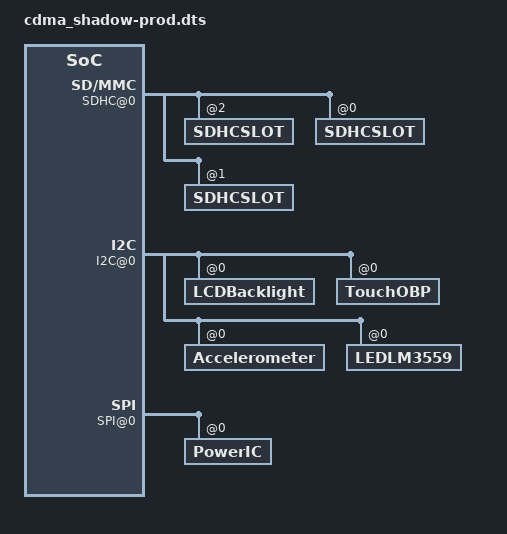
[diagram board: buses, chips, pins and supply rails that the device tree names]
/* Motorola Droid X - production version */

/dts-v1/;

/ {

	Aliases@0 {
	};

	Chosen@0 {
		bp_model = "CDMA";
		formfactor = <0x3000000>;
		last_compat_version = <0xfcb73201>;
		omap3630_rev = <0x36301000>;
		product = <0x36120000>;
		usb_id_prod_name = "MB810";
		version = <0xfcb73201>;
	};

	Machine@0 {
		cpu_tier = "10";
	};

	System@0 {

		DisplayBacklight@0 {
			tablet_lcd = [01];
			class = "DisplayBacklight";
			ruth_lcd = [00];
			type = <0xd000000>;
		};

		Display@1 {
			gpio_int = <0x19000000>;
			gpio_pwr_en = <0x1a000000>;
			gpio_mux_select = <0x7000000>;
			gpio_mux_en = <0x45000000>;
			class = "Display";
			type = <0x1900>;
			cec_reg_name = "vusb";
		};

		Keyreset@0 {
			keyup = <0x10010000 0x0>;
			crash = <0x73000000>;
			class = "Keyreset";
			keydown = <0x8b000000 0x9e000000 0xd3000000 0x0>;
			type = <0x11000000>;
		};

		LEDController@2 {
			dev_name_green = "green";
			class = "LEDController";
			dev_name_red = "red";
			type = <0x5002100>;
			dev_name_blue = "blue";
		};

		SDHC@0 {
			bind_device_to_host = [01];
			class = "SDHC";
			type = <0x8000300>;

			SDHCSLOT@2 {
				card_detection = <0x1000000>;
				sdcnum = [03];
				host_capability = <0x11000000>;
				card_connect = <0x3000000>;
			};

			SDHCSLOT@0 {
				card_detection = <0x1000000>;
				host_capability = <0x11000000>;
				pwr_supply = <0x2000000>;
				card_connect = <0x1000000>;
			};

			SDHCSLOT@1 {
				card_detection = <0x0>;
				host_capability = <0x11010000>;
				card_connect = <0x2000000>;
			};
		};

		PROX@0 {
			pwr_supply = <0x0>;
			class = "PROX";
			type = <0x1b00>;
		};

		I2C@0 {
			bus3devices = "HP_GEN_LENS,tda19989,ov8810,lm3559_led";
			bus1devices = "qtouch-obp-ts,lm3530_led,airc";
			class = "I2C";
			bus2devices = "akm8973,kxtf9";
			type = <0x3000100>;

			LCDBacklight@0 {
				zone_target_4 = [7b];
				zone_target_3 = [7b];
				zone_target_0 = [15];
				als_resistor_sel = [02];
				manual_current = [37];
				als_config = [ac];
				zone_boundary_2 = [c6];
				als_zone_info = [00];
				zone_boundary_3 = [c6];
				upper_curr_sel = [06];
				lens_loss_coeff = [01];
				gen_config = [3b];
				zone_boundary_0 = [03];
				class = "LCDBacklight";
				zone_target_1 = [30];
				zone_target_2 = [68];
				brightness_control = [00];
				lower_curr_sel = [03];
				manual_als_config = [2d];
				type = <0x2000b00>;
				zone_boundary_1 = [54];
				power_up_gen_config = [27];
				brightness_ramp = [00];
			};

			TouchOBP@0 {
				abs_min_x = <0x23000000>;
				abs_min_y = <0x14000000>;
				abs_max_w = <0x23000000>;
				abs_max_x = <0xf5030000>;
				abs_max_y = <0xe8030000>;
				boot_i2c_address = [24];
				class = "TouchOBP";
				i2c,address = <0x4a000000>;
				obj_t22 = [05 00 00 19 00 e7 ff 04 14 00 00 07 0b 0e 10 16 04];
				obj_t28 = [01 00 03 04 08 0a];
				obj_t7 = [0a 0a 19];
				obj_t8 = <0xc000000 0x96000500>;
				obj_t9 = [0b 00 00 13 0b 00 10 2d 02 04 19 0a 03 30 02 05 05 05 00 00 00 00 05 00 2f 0c ca 37 86 5f];
				nv_checksum = <0xbcf00000>;
				type = <0x6000700>;
			};

			Accelerometer@0 {
				axis_map_x = [00];
				axis_map_y = [01];
				axis_map_z = [02];
				class = "Accelerometer";
				negate_x = [01];
				negate_y = [00];
				negate_z = [01];
				type = <0x1800>;
			};

			LEDLM3559@0 {
				device_available = [01];
				class = "LEDLM3559";
				lm3559_flags = [2c];
				type = <0x3000b00>;
			};
		};

		Keypad@0 {
			class = "Keypad";
			columnregister = <0x2b000000 0x38000000 0x39000000 0x35000000 0x36000000 0x37000000 0x3a000000 0x3f000000>;
			columns = <0x8000000>;
			dev_name = "cdma_shadow-keypad";
			wakeints = <0x1000000>;
			maps = <0x73007200 0x8b00e700 0x0 0xd400 0xd3000000 0x0 0x0 0x66009e00 0xd9000000 0x0 0x0 0x0 0x38000000 0x6000b00 0x0 0xe300 0x700 0x2000000 0x0 0x3d000000 0x8000300 0x0 0x3e00 0x900 0x4000000 0x0 0xe4000000 0xa000500>;
			rowregister = <0x27000000 0x25000000 0x28000000 0x29000000 0x26000000 0x23000000 0x22000000>;
			rows = <0x7000000>;
			keycodes-bugtogo = <0x8b000000 0xd9000000>;
			wakeupregister = <0x27000000>;
			type = <0x1000000>;
		};

		Modem@0 {
			class = "Modem";
			type = <0x1e00>;
		};

		GPIODev@0 {
			class = "GPIODev";
			init = <0x3b000000 0x6770735f 0x72657365 0x74002020 0x20202020 0x20202000 0x8000000 0x17000000 0x6770735f 0x7374616e 0x64627900 0x20202020 0x20202000 0x8000000 0x8000000 0x62745f77 0x616b6500 0x20202020 0x20202020 0x20202000 0x8000000 0x7000000 0x68646d69 0x5f6d7578 0x5f73656c 0x65637400 0x20202000 0x8000000 0x45000000 0x68646d69 0x5f6d7578 0x5f656e5f 0x6e002020 0x20202000 0x8000000 0xb2000000 0x62745f68 0x6f737477 0x616b6500 0x20202020 0x20202000 0x2000000>;
			type = <0xa000300>;
		};

		LinearVibrator@0 {
			gpio = <0x9000000>;
			cycle = <0x710c0000>;
			class = "LinearVibrator";
			period = <0xe2180000>;
			supported = <0x1000000>;
			type = <0x2000000>;
			linear_vib_only = <0x1000000>;
		};

		Display@0 {
			disp_intf = [04];
			dsi_data2_lane = [03];
			pixel_fmt = <0x5000000>;
			pck_div = [04 00];
			dsi_data1_pol = [00];
			dsi_data1_lane = [02];
			dispc_timing_hbp = [02 00];
			dispc_timing_hfp = [00 00];
			dsi_clk_pol = [00];
			regm = [aa 00];
			dispc_timing_vfp = [00 00];
			dsi_clk_lane = [01];
			lp_clk_div = [0a 00];
			regm4 = [05 00];
			class = "Display";
			lck_div = [01 00];
			dispc_timing_hsw = [02 00];
			dispc_timing_vbp = [01 00];
			phy_height_mm = [5f 00];
			disp_hw_type = [04];
			gpio_reset = <0x7e000000>;
			type = <0x1a00>;
			byte_pp = [03];
			phy_width_mm = [35 00];
			regm3 = [05 00];
			dispc_timing_vsw = [01 00];
			height = [56 03];
			width = [e0 01];
			regn = [0d 00];
			dsi_data2_pol = [00];
		};

		GPIO@0 {
			class = "GPIO";
			signalmap = <0x1c000000 0x616b6d38 0x3937335f 0x72657365 0x74202020 0x20202000 0xa0000000 0x6c6d3335 0x33305f72 0x65736574 0x20202020 0x20202000 0x1d000000 0x6c6d3335 0x33305f69 0x6e742020 0x20202020 0x20202000 0xaf000000 0x616b6d38 0x3937335f 0x696e7420 0x20202020 0x20202000 0xb3000000 0x62745f72 0x65736574 0x5f622020 0x20202020 0x20202000 0x8000000 0x62745f77 0x616b655f 0x62202020 0x20202020 0x20202000 0xb2000000 0x62745f68 0x6f73745f 0x77616b65 0x5f622020 0x20202000 0xba000000 0x776c616e 0x5f726573 0x65742020 0x20202020 0x20202000 0x64000000 0x73696c65 0x6e63655f 0x64617461 0x20202020 0x20202000 0xb5000000 0x7669625f 0x636f6e74 0x726f6c5f 0x656e2020 0x20202000 0xb0000000 0x706f7765 0x725f6f66 0x66202020 0x20202020 0x20202000 0x6d000000 0x746f7563 0x685f7061 0x6e656c5f 0x696e7420 0x20202000 0xa4000000 0x746f7563 0x685f7061 0x6e656c5f 0x72737420 0x20202000 0x2a000000 0x666d5f65 0x6e61626c 0x65202020 0x20202020 0x20202000 0x7f000000 0x6970635f 0x6f5f6270 0x5f707772 0x6f6e2020 0x20202000 0x80000000 0x6970635f 0x6f5f6270 0x5f707368 0x6f6c6420 0x20202000 0x9d000000 0x6970635f 0x6f5f6270 0x5f666c61 0x73685f65 0x6e202000 0x81000000 0x6970635f 0x695f6270 0x5f726573 0x6f757420 0x20202000 0x8d000000 0x6970635f 0x695f6270 0x5f726561 0x64792020 0x20202000 0x3b000000 0x6970635f 0x695f6270 0x5f726561 0x64793220 0x20202000 0x8c000000 0x6970635f 0x6f5f7573 0x625f6279 0x70617373 0x20202000 0x8e000000 0x6970635f 0x6f5f7573 0x625f7375 0x73702020 0x20202000 0x9b000000 0x6970635f 0x6f5f7573 0x625f7478 0x656e5f6e 0x20202000 0x7000000 0x68646d69 0x5f6d7578 0x5f73656c 0x65637420 0x20202000 0x45000000 0x68646d69 0x5f6d7578 0x5f656e5f 0x6e202020 0x20202000 0x16000000 0x61636365 0x6c315f69 0x6e742020 0x20202020 0x20202000 0x19000000 0x68646d69 0x5f696e74 0x20202020 0x20202020 0x20202000 0xb4000000 0x70726f78 0x696d6974 0x795f696e 0x74202020 0x20202000>;
			type = <0x3000300>;

			HallEffect@0 {
				device_available = [01];
				class = "HallEffect";
				type = <0x1700>;
			};
		};

		SimDevice@0 {
			sim_availability = [00];
			class = "SimDevice";
			type = <0x10000000>;
		};

		Feature@0 {
			feature_no_nand = [01];
			feature_cam_regulators = "vcam";
			class = "Feature";
			feature_mipi_cam = [01];
			feature_hdmi = [01];
			type = <0xf000000>;
		};

		Audio@0 {
			mic3 = <0x1000000>;
			class = "Audio";
			analog_downlink = <0x1000000>;
			i2s_bp = <0x1000000>;
			type = <0xb000000>;
		};

		IOMUX@0 {
			offmodewkupsinit = <0x1a0a0101 0x5a0a 0x10101>;
			offmodeinit = [7a 00 00 01 00 00 7c 00 00 01 00 00 7e 00 00 01 00 00 80 00 00 01 00 00 82 00 00 01 00 00 84 00 00 01 00 01 86 00 00 01 00 00 88 00 00 01 00 00 be 00 00 01 01 01 d2 00 00 01 00 01 16 01 00 01 00 00 18 01 00 01 00 00 34 01 00 01 00 00 36 01 00 01 00 00 38 01 00 01 00 00 3a 01 00 01 00 00 2e 01 00 01 00 01 08 01 00 01 00 01 d6 01 00 01 00 01 da 01 00 01 00 01 d0 01 00 01 00 01 ec 05 00 01 00 01 f0 05 00 01 00 01 d4 01 00 01 00 01 d2 01 00 01 00 00];
			padwkupsinit = <0x140a0400 0x160a07 0x1a0a 0x4010018 0xa040000 0x560a0400 0x540a04 0x580a 0x400005a 0xa040103>;
			class = "IOMUX";
			type = <0x4000300>;
			padinit = [da 01 04 01 00 64 02 00 00 00 be 00 04 01 01 d0 00 04 01 03 d4 00 00 00 00 d6 00 00 00 00 d8 00 00 00 00 da 00 04 00 00 dc 00 01 00 00 de 00 01 00 00 e0 00 01 00 00 e2 00 01 00 00 e4 00 01 00 00 e6 00 01 00 00 e8 00 00 00 00 ea 00 00 00 00 ec 00 00 00 00 ee 00 00 00 00 f0 00 00 00 00 f2 00 00 00 00 f4 00 00 00 00 f6 00 00 00 00 f8 00 00 00 00 fa 00 00 00 00 fc 00 00 00 00 fe 00 00 00 00 00 01 00 00 00 02 01 00 00 00 04 01 00 00 00 06 01 00 00 00 08 01 00 00 00 0a 01 00 00 00 0c 01 07 00 00 0e 01 07 00 00 12 01 07 00 00 14 01 04 00 00 16 01 02 00 00 18 01 02 00 00 1a 01 07 00 00 1c 01 07 00 00 1e 01 07 00 00 20 01 07 00 00 22 01 07 00 03 24 01 07 00 03 26 01 07 00 03 28 01 07 00 03 2a 01 04 01 03 2c 01 07 00 00 10 01 00 00 00 2e 01 04 01 00 32 01 07 00 00 30 01 07 00 00 34 01 00 00 00 36 01 00 00 00 38 01 00 00 00 3a 01 00 00 00 8e 01 04 00 00 8c 01 07 00 00 6c 01 04 00 00 6e 01 04 01 01 70 01 04 00 00 72 01 04 00 03 7c 01 00 00 00 7e 01 00 00 00 80 01 00 01 03 82 01 00 01 01 84 01 06 01 01 86 01 06 01 01 88 01 06 01 01 8a 01 06 00 00 9a 01 04 01 00 9c 01 04 00 03 ec 05 04 01 00 ee 05 04 00 00 f0 05 04 01 00 f2 05 04 01 00 f4 05 04 00 00 f8 05 04 00 00 fa 05 04 01 00 94 01 04 00 00 44 01 00 01 00 58 01 00 01 00 5a 01 00 01 03 5c 01 00 01 03 5e 01 00 01 03 60 01 00 01 03 62 01 00 01 03 64 01 00 01 03 66 01 00 01 03 68 01 00 01 03 6a 01 00 01 03 d8 05 02 01 00 da 05 02 01 03 e2 05 02 01 03 e4 05 02 01 03 e6 05 02 01 03 e8 05 02 01 03 e2 01 04 00 00 d2 01 04 00 00 d4 01 07 01 00 de 01 04 00 00 d8 01 04 00 00 da 01 04 01 00 be 01 00 01 03 c0 01 00 01 03 dc 01 01 00 00];
		};

		SPI@0 {
			class = "SPI";
			type = <0x7000300>;

			PowerIC@0 {
				regulator_init = [06 00 00 00 40 77 1b 00 40 77 1b 00 08 00 00 00 00 01 01 08 00 00 00 38 9c 1c 00 38 9c 1c 00 01 00 00 00 01 00 01 0d 00 00 00 d8 57 2a 00 d8 57 2a 00 09 00 00 00 00 00 01 0e 00 00 00 d8 57 2a 00 d8 57 2a 00 09 00 00 00 01 00 01 0f 00 00 00 d8 57 2a 00 d8 57 2a 00 09 00 00 00 01 00 01 12 00 00 00 40 77 1b 00 20 40 2c 00 09 00 00 00 00 00 00 13 00 00 00 40 77 1b 00 20 40 2c 00 09 00 00 00 00 00 00];
				class = "PowerIC";
				spiinit = <0x9c000000 0x0>;
				vio_supply_converter = [00];
				type = <0x6000300>;
				regulator_mode = [06 00 00 00 43 00 08 00 00 00 00 00 14 00 00 00 00 00 0d 00 00 00 2c 00 0e 00 00 00 00 00 0f 00 00 00 00 00 16 00 00 00 14 00];
			};
		};

		VideoOut@0 {
			max_height = [d0 02];
			max_buffer_size = <0x301c00>;
			class = "VideoOut";
			max_width = [00 05];
			type = <0xe000000>;
		};

		LEDController@1 {
			class = "LEDController";
			dev_name = "button-backlight";
			type = <0x1002100>;
		};

		LEDController@0 {
			class = "LEDController";
			init = [3c 00];
			type = <0x2100>;
		};
	};
};
